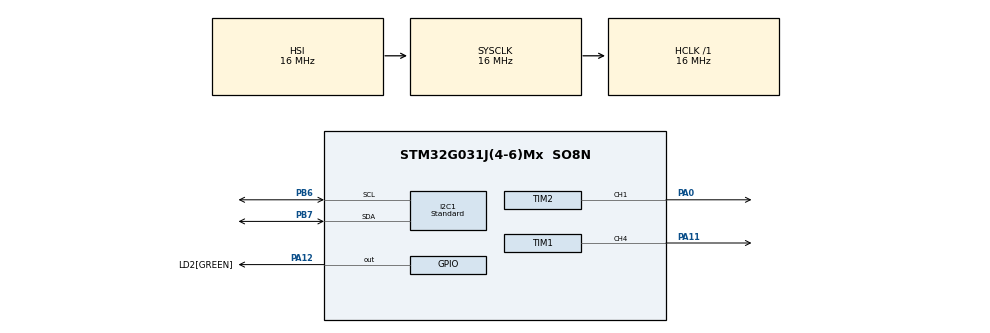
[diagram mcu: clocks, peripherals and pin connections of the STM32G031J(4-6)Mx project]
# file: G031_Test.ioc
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I2C1.I2C_Speed_Mode=I2C_Standard
IWDG.Prescaler=IWDG_PRESCALER_256
IWDG.Reload=4095
IWDG.Window=4095
Mcu.Family=STM32G0
Mcu.Name=STM32G031J(4-6)Mx
Mcu.Package=SO8N
NVIC.TIM16_IRQn=true\:0\:0\:false\:false\:true\:true\:true\:true
PA0.Signal=S_TIM2_CH1_ETR
PA11\ [PA9].Signal=S_TIM1_CH4
PA12\ [PA10].GPIO_Label=LD2[GREEN]
PA12\ [PA10].Signal=GPIO_Output
PA14-BOOT0__PA15__PB5__PB6.StandardMode=true
PB0__PB1__PA8__PA11\ [PA9].StandardMode=true
PB6.GPIO_Pu=GPIO_NOPULL
PB6.Mode=I2C
PB6.Signal=I2C1_SCL
PB7.GPIO_Pu=GPIO_NOPULL
PB7.Mode=I2C
PB7.Signal=I2C1_SDA
PC14-OSC32_IN\ (PC14)__PB7__PB8__PB9.StandardMode=true
PF2\ -\ NRST__PA0__PA1__PA2.StandardMode=true
ProjectManager.HeapSize=0x200
ProjectManager.StackSize=0x400
ProjectManager.TargetToolchain=STM32CubeIDE
RCC.ADCFreq_Value=16000000
RCC.AHBFreq_Value=16000000
RCC.CortexFreq_Value=16000000
RCC.EXTERNAL_CLOCK_VALUE=12288000
RCC.HCLKFreq_Value=16000000
RCC.HSE_VALUE=8000000
RCC.HSI_VALUE=16000000
RCC.LSE_VALUE=32768
RCC.SYSCLKFreq_VALUE=16000000
RCC.VCOOutputFreq_Value=128000000
SH.S_TIM1_CH4.0=TIM1_CH4,PWM Generation4 CH4
SH.S_TIM2_CH1_ETR.0=TIM2_CH1,PWM Generation1 CH1
TIM1.Channel-PWM\ Generation4\ CH4=TIM_CHANNEL_4
TIM1.Period=100-1
TIM1.Prescaler=16000-1
TIM1.Pulse-PWM\ Generation4\ CH4=10
TIM14.Prescaler=16-1
TIM16.Period=1000-1
TIM16.Prescaler=400-1
TIM2.Channel-PWM\ Generation1\ CH1=TIM_CHANNEL_1
TIM2.Period=200
TIM2.Prescaler=0
TIM2.Pulse-PWM\ Generation1\ CH1=45
VP_IWDG_VS_IWDG.Mode=IWDG_Activate
VP_TIM14_VS_ClockSourceINT.Mode=Enable_Timer
VP_TIM16_VS_ClockSourceINT.Mode=Enable_Timer
VP_TIM1_VS_ClockSourceINT.Mode=Internal
board=STM32G0316-DISCO

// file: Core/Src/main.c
/* USER CODE BEGIN Header */
/**
  ******************************************************************************
  * @file           : main.c
  * @brief          : Main program body
  ******************************************************************************
  * @attention
  *
  * Copyright (c) 2022 STMicroelectronics.
  * All rights reserved.
  *
  * This software is licensed under terms that can be found in the LICENSE file
  * in the root directory of this software component.
  * If no LICENSE file comes with this software, it is provided AS-IS.
  *
  ******************************************************************************
  */
/* USER CODE END Header */
#include "main.h"
#include "i2c.h"
#include "iwdg.h"
#include "tim.h"
#include "gpio.h"

/* USER CODE BEGIN Includes */
#include "../../User/Main/app.h"

/* USER CODE END Includes */

void SystemClock_Config(void);

int main(void)
{

  /* MCU Configuration--------------------------------------------------------*/

  /* Reset of all peripherals, Initializes the Flash interface and the Systick. */
  HAL_Init();

  /* Configure the system clock */
  SystemClock_Config();

  /* Initialize all configured peripherals */
  MX_GPIO_Init();
  MX_I2C1_Init();
  MX_TIM14_Init();
  MX_TIM1_Init();
  MX_IWDG_Init();
  MX_TIM16_Init();
  MX_TIM2_Init();
  /* USER CODE BEGIN 2 */

  app_main();
  /* USER CODE END 2 */

  /* Infinite loop */
  while (1)
  {

    /* USER CODE BEGIN 3 */

	  /**
	   * This part of the code should never be accessed
	   */

  }
  /* USER CODE END 3 */
}

void SystemClock_Config(void)
{
  RCC_OscInitTypeDef RCC_OscInitStruct = {0};
  RCC_ClkInitTypeDef RCC_ClkInitStruct = {0};

  /** Configure the main internal regulator output voltage
  */
  HAL_PWREx_ControlVoltageScaling(PWR_REGULATOR_VOLTAGE_SCALE1);

  /** Initializes the RCC Oscillators according to the specified parameters
  * in the RCC_OscInitTypeDef structure.
  */
  RCC_OscInitStruct.OscillatorType = RCC_OSCILLATORTYPE_HSI|RCC_OSCILLATORTYPE_LSI;
  RCC_OscInitStruct.HSIState = RCC_HSI_ON;
  RCC_OscInitStruct.HSIDiv = RCC_HSI_DIV1;
  RCC_OscInitStruct.HSICalibrationValue = RCC_HSICALIBRATION_DEFAULT;
  RCC_OscInitStruct.LSIState = RCC_LSI_ON;
  RCC_OscInitStruct.PLL.PLLState = RCC_PLL_NONE;
  if (HAL_RCC_OscConfig(&RCC_OscInitStruct) != HAL_OK)
  {
    Error_Handler();
  }

  /** Initializes the CPU, AHB and APB buses clocks
  */
  RCC_ClkInitStruct.ClockType = RCC_CLOCKTYPE_HCLK|RCC_CLOCKTYPE_SYSCLK
                              |RCC_CLOCKTYPE_PCLK1;
  RCC_ClkInitStruct.SYSCLKSource = RCC_SYSCLKSOURCE_HSI;
  RCC_ClkInitStruct.AHBCLKDivider = RCC_SYSCLK_DIV1;
  RCC_ClkInitStruct.APB1CLKDivider = RCC_HCLK_DIV1;

  if (HAL_RCC_ClockConfig(&RCC_ClkInitStruct, FLASH_LATENCY_0) != HAL_OK)
  {
    Error_Handler();
  }
}

void Error_Handler(void)
{
  __disable_irq();
  while (1)
  {
  }
}
